# AT32F456xx_v2 register map
Vendor: Keil; Series: AT32F456; File version: 1.0
CPU: CM4 r0p1, little endian, no MPU, FPU, 4 interrupt priority bits
Registers are 32-bit, read-write, reset 0x0 unless marked. A register's access mark holds for its fields unless they carry their own. Offsets are from the block's base; [hi:lo] are bit positions; {n}, {i} and the like mark numbered series.

## CAN1 — Can controller area network
Base 0x40006400
Same registers: CAN2 0x40006800, CAN3 0x40006C00
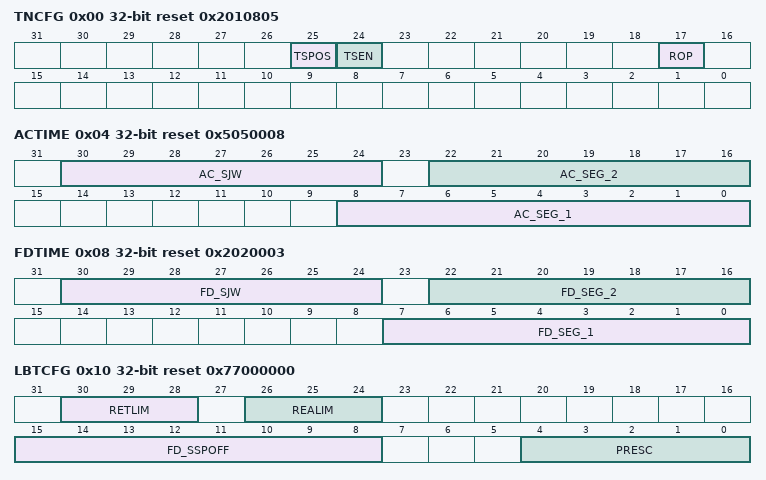
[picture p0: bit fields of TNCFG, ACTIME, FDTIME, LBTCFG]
0x00 TNCFG reset 0x2010805 — Timestamp and node config register
  [25] TSPOS — Time stamping position
  [24] TSEN — Time stamping enable
  [17] ROP — Restricted operation
0x04 ACTIME reset 0x5050008 — Classic-CAN Bit Timing register
  [30:24] AC_SJW — Classic-CAN Synchronization Jump Width
  [22:16] AC_SEG_2 — Classic-CAN Bit Timing Segment 2
  [8:0] AC_SEG_1 — Classic-CAN Bit Timing Segment 1
0x08 FDTIME reset 0x2020003 — CAN-FD Bit Timing register
  [30:24] FD_SJW — CAN-FD Synchronization Jump Width
  [22:16] FD_SEG_2 — CAN-FD Bit Timing Segment 2
  [7:0] FD_SEG_1 — CAN-FD Bit Timing Segment 1
0x10 LBTCFG reset 0x77000000 — limit and bit time config register
  [30:28] RETLIM — Retransmission limit
  [26:24] REALIM — Re-arbitration limit
  [15:8] FD_SSPOFF — CAN-FD Secondary sample point offset
  [4:0] PRESC — Bit Time Prescaler
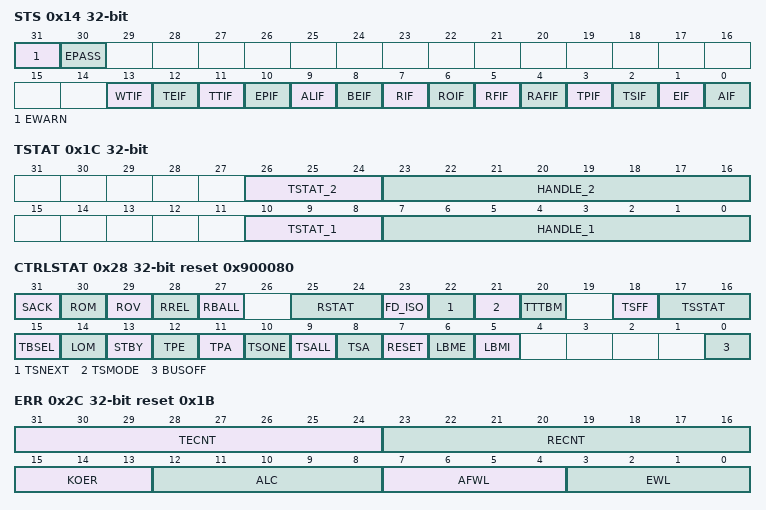
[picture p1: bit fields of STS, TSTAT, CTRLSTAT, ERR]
0x14 STS — Status register
  [31] EWARN ro — Error warning limit reached
  [30] EPASS ro — Error passive status
  [13] WTIF — Watch trigger interrupt flag
  [12] TEIF — Trigger error interrupt flag
  [11] TTIF — Time trigger interrupt flag
  [10] EPIF — Error passive interrupt flag
  [9] ALIF — Arbitration lost interrupt flag
  [8] BEIF — Bus error interrupt flag
  [7] RIF — Receive interrupt flag
  [6] ROIF — RxBuf overflow interrupt flag
  [5] RFIF — RxBuf full interrupt flag
  [4] RAFIF — RxBuf almost full interrupt flag
  [3] TPIF — Transmission PTB completed interrupt flag
  [2] TSIF — Transmission STB completed interrupt flag
  [1] EIF — Error interrupt flag
  [0] AIF — Abort interrupt flag
0x1C TSTAT — Transmit Status register
  [26:24] TSTAT_2 — Final transmission status code
  [23:16] HANDLE_2 — Final handle for frame identification
  [10:8] TSTAT_1 — Current transmission status code
  [7:0] HANDLE_1 — Current handle for frame identification
0x20 TTS — Transmission time stamp register
  [31:0] TTS — Transmission time stamp
0x28 CTRLSTAT reset 0x900080 — Control and Status register
  [31] SACK — self-acknowledge
  [30] ROM — Receive buffer overflow mode
  [29] ROV ro — Receive buffer overflow
  [28] RREL — Receive buffer release
  [27] RBALL — Receive buffer stores all data frames
  [25:24] RSTAT — Receive buffer status
  [23] FD_ISO — CAN-FD ISO mode
  [22] TSNEXT — Transmit buffer secondary next
  [21] TSMODE — Transmit buffer secondary operation mode
  [20] TTTBM — TTCAN transmit buffer mode
  [18] TSFF — Transmit secondary buffer full flag
  [17:16] TSSTAT — Transmit secondary buffer status
  [15] TBSEL — Transmit buffer select
  [14] LOM — Listen only mode
  [13] STBY — Transceiver standby mode
  [12] TPE — Transmit primary enable
  [11] TPA — Transmit primary abort
  [10] TSONE — Transmit secondary one frame
  [9] TSALL — Transmit secondary all frames
  [8] TSA — Transmit secondary abort
  [7] RESET — RESET request bit
  [6] LBME — Loop back mode, external
  [5] LBMI — Loop back mode, internal
  [0] BUSOFF
0x2C ERR reset 0x1B — Error register
  [31:24] TECNT ro — Transmit error count
  [23:16] RECNT ro — Receive error count
  [15:13] KOER ro — Error code
  [12:8] ALC ro — Arbitration Lost Capture
  [7:4] AFWL — Almost full warning limit of receive buffer
  [3:0] EWL — Programmable error warning limit
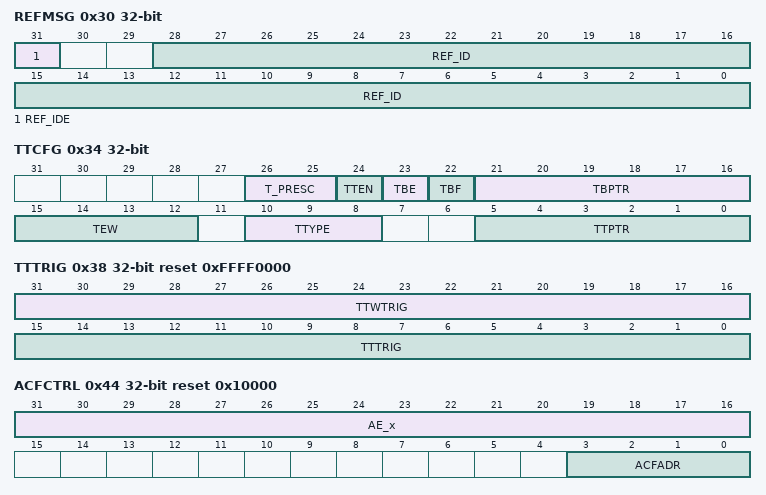
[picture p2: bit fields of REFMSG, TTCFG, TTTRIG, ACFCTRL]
0x30 REFMSG — Reference message register
  [31] REF_IDE — Reference message IDE bit
  [28:0] REF_ID — Reference message identifier
0x34 TTCFG — TTCAN Configuration register
  [26:25] T_PRESC — TTCAN timer prescaler
  [24] TTEN — TTCAN enable
  [23] TBE — Set TB slot to Empty
  [22] TBF — Set TB slot to Filled
  [21:16] TBPTR — Pointer to a TB frame slot
  [15:12] TEW — Transmit enable window
  [10:8] TTYPE — Trigger type
  [5:0] TTPTR — Transmit trigger TB slot pointer
0x38 TTTRIG reset 0xFFFF0000 — TTCAN Trigger Time register
  [31:16] TTWTRIG — TTCAN Watch trigger time
  [15:0] TTTRIG — TTCAN Trigger time
0x44 ACFCTRL reset 0x10000 — Acceptance Filter Control register
  [31:16] AE_x — Acceptance filter_x(0..15) enable
  [3:0] ACFADR — Acceptance filter address
0x48 FCID — Filter code identifier register
  [31:0] FCID_x — Filter code identifier
0x4C FCFMT — Filter code format register
  [31:0] FCFMT_x — Filter code format
0x50 FCTYP — Filter code type register
  [31:0] FCTYP_x — Filter code type
0x58 FMID reset 0xFFFFFFFF — Filter mask identifier register
  [31:0] FMID_x — Filter mask identifier
0x5C FMFMT reset 0xFFFFFFFF — Filter mask format register
  [31:0] FMFMT_x — Filter mask format
0x60 FMTYP reset 0xFFFFFFFF — Filter mask type register
  [31:0] FMTYP_x — Filter mask type
0x70 RBID — RBUF Identifier register
  [31:0] RBID — RBUF Identifier
0x74 RBFMT — RBUF Format register
  [31:0] RBFMT — RBUF Format
0x78 RBTYP — RBUF Type register
  [31:0] RBTYP — RBUF Type
{0x80+4i} RBDAT{i} (i=0..18) — RBUF Data{i} register
  [31:0] RBDAT{i} — RBUF Data{i}
0xCC TBID — TBUF Identifier register
  [31:0] TBID — TBUF Identifier
0xD0 TBFMT — TBUF Format register
  [31:0] TBFMT — TBUF Format
0xD4 TBTYP — TBUF Type register
  [31:0] TBTYP — TBUF Type
{0xDC+4i} TBDAT{i} (i=0..15) — TBUF Data{i} register
  [31:0] TBDAT{i} — TBUF Data{i}
0x124 LLCFORMAT — LLC Frame Calculator Input LLCFORMAT register
  [31:0] LLCFORMAT — Input LLC FORMAT
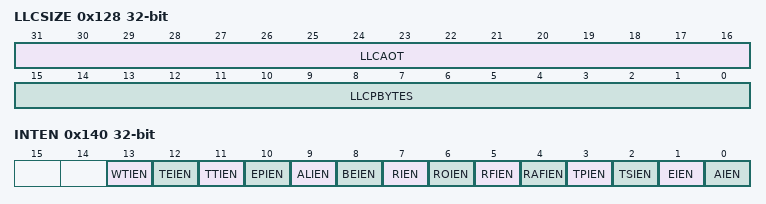
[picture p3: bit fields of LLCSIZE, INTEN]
0x128 LLCSIZE — LLC Frame Calculator Output LLCSIZE register
  [31:16] LLCAOT — Output LLC address offset of time-stamps
  [15:0] LLCPBYTES — Output LLC frame payload bytes
0x140 INTEN — interrupt enable register
  [13] WTIEN — Watch trigger interrupt enable
  [12] TEIEN — Trigger error interrupt enable
  [11] TTIEN — Time trigger interrupt enable
  [10] EPIEN — Error passive interrupt enable
  [9] ALIEN — Arbitration lost interrupt enable
  [8] BEIEN — Bus error interrupt enable
  [7] RIEN — Receive interrupt enable
  [6] ROIEN — RxBuf overflow interrupt enable
  [5] RFIEN — RxBuf full interrupt enable
  [4] RAFIEN — RxBuf almost full interrupt enable
  [3] TPIEN — Transmission PTB completed interrupt enable
  [2] TSIEN — Transmission STB completed interrupt enable
  [1] EIEN — Error interrupt enable
  [0] AIEN — Abort interrupt enable

## Notices in the file
Copyright (C) 2012-2014 ARM Limited. All rights reserved.
Purpose: System Viewer Description (SVD) Example (Schema Version 1.1)
This is a description of a none-existent and incomplete device
for demonstration purposes only.
Redistribution and use in source and binary forms, with or without
modification, are permitted provided that the following conditions are met:
- Redistributions of source code must retain the above copyright
notice, this list of conditions and the following disclaimer.
- Redistributions in binary form must reproduce the above copyright
notice, this list of conditions and the following disclaimer in the
documentation and/or other materials provided with the distribution.
- Neither the name of ARM nor the names of its contributors may be used
to endorse or promote products derived from this software without
specific prior written permission.
THIS SOFTWARE IS PROVIDED BY THE COPYRIGHT HOLDERS AND CONTRIBUTORS "AS IS"
AND ANY EXPRESS OR IMPLIED WARRANTIES, INCLUDING, BUT NOT LIMITED TO, THE
IMPLIED WARRANTIES OF MERCHANTABILITY AND FITNESS FOR A PARTICULAR PURPOSE
ARE DISCLAIMED. IN NO EVENT SHALL COPYRIGHT HOLDERS AND CONTRIBUTORS BE
LIABLE FOR ANY DIRECT, INDIRECT, INCIDENTAL, SPECIAL, EXEMPLARY, OR
CONSEQUENTIAL DAMAGES (INCLUDING, BUT NOT LIMITED TO, PROCUREMENT OF
SUBSTITUTE GOODS OR SERVICES; LOSS OF USE, DATA, OR PROFITS; OR BUSINESS
INTERRUPTION) HOWEVER CAUSED AND ON ANY THEORY OF LIABILITY, WHETHER IN
CONTRACT, STRICT LIABILITY, OR TORT (INCLUDING NEGLIGENCE OR OTHERWISE)
ARISING IN ANY WAY OUT OF THE USE OF THIS SOFTWARE, EVEN IF ADVISED OF THE
POSSIBILITY OF SUCH DAMAGE.
